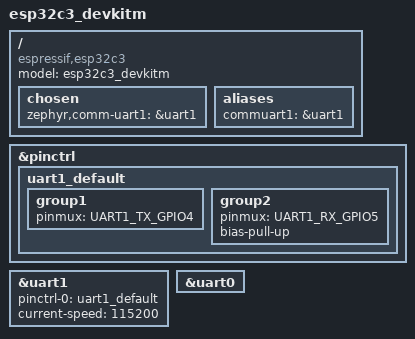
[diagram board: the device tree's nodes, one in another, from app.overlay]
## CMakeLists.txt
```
# SPDX-License-Identifier: Apache-2.0

cmake_minimum_required(VERSION 3.20.0)

find_package(Zephyr REQUIRED HINTS $ENV{ZEPHYR_BASE})
project(hello_world)

target_sources(app PRIVATE src/main.c)
target_include_directories(app PRIVATE 
    /home/user/csse4011/repo/oslib/scu_drivers/scu_sensors/
    /home/user/csse4011/repo/oslib/scu_drivers/scu_hci/
    /home/user/csse4011/repo/oslib/ahu_drivers/ahu_hci/)


target_sources(app PRIVATE
    src/main.c
    /home/user/csse4011/repo/oslib/scu_drivers/scu_sensors/scu_sensors.c
    /home/user/csse4011/repo/oslib/scu_drivers/scu_hci/scu_hci.c
    /home/user/csse4011/repo/oslib/ahu_drivers/ahu_hci/ahu_hci.c)
```

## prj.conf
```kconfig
CONFIG_GPIO=y
CONFIG_PRINTK=y
CONFIG_SERIAL=y
CONFIG_UART_INTERRUPT_DRIVEN=y
CONFIG_STDOUT_CONSOLE=y
CONFIG_I2C=y
CONFIG_SPI=y

#-----------------------------SHELL_CONF--------------------------------------
CONFIG_UART_LINE_CTRL=y
CONFIG_SHELL=y
CONFIG_SHELL_PROMPT_UART="CSSE4011:~$ "
CONFIG_SHELL_CMDS=y
CONFIG_SHELL_TAB=y
CONFIG_SHELL_TAB_AUTOCOMPLETION=y
CONFIG_SHELL_VT100_COLORS=y
#-----------------------------------------------------------------------------

#-----------------------------SHELL_LOGGING-----------------------------------
CONFIG_LOG=y
CONFIG_LOG_PRINTK=y
CONFIG_LOG_BACKEND_UART=y
#-----------------------------------------------------------------------------
```

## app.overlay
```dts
#include <espressif/esp32c3.dtsi>

/ {
    model = "esp32c3_devkitm";
    compatible = "espressif,esp32c3";
    chosen {
        zephyr,comm-uart1 = &uart1; // set UART1 for communication
    };

    aliases {
        commuart1 = &uart1; // create an alias for UART1
    };
};

&pinctrl {
    uart1_default: uart1_default {
        group1 {
            pinmux = < UART1_TX_GPIO4 >;
        };
        group2 {
            pinmux = < UART1_RX_GPIO5 >;
            bias-pull-up;
        };
    };
};

&uart1 {
    status = "okay";
    pinctrl-0 = < &uart1_default >;
    pinctrl-names = "default";
    current-speed = <115200>;
};

&uart0 {
    status = "okay";
};
```

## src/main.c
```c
/*
 * Copyright (c) 2022 Libre Solar Technologies GmbH
 *
 * SPDX-License-Identifier: Apache-2.0
 */

#include <zephyr/kernel.h>
#include <zephyr/device.h>
#include <zephyr/drivers/uart.h>
#include <stdio.h>
#include <string.h>

/* change this to any other UART peripheral if desired */
#define UART_DEVICE_NODE DT_ALIAS(commuart1)

#define MSG_SIZE 32

/* queue to store up to 10 messages (aligned to 4-byte boundary) */
K_MSGQ_DEFINE(uart_msgq, MSG_SIZE, 10, 4);

static const struct device *const uart_dev = DEVICE_DT_GET(UART_DEVICE_NODE);

/* receive buffer used in UART ISR callback */
static char rx_buf[MSG_SIZE];
static int rx_buf_pos;

/*
 * Read characters from UART until line end is detected. Afterwards push the
 * data to the message queue.
 */
void serial_cb(const struct device *dev, void *user_data)
{
	uint8_t c;

	if (!uart_irq_update(uart_dev)) {
		return;
	}

	if (!uart_irq_rx_ready(uart_dev)) {
		return;
	}

	/* read until FIFO empty */
	while (uart_fifo_read(uart_dev, &c, 1) == 1) {
		if ((c == '\n' || c == '\r') && rx_buf_pos > 0) {
			/* terminate string */
			rx_buf[rx_buf_pos] = '\0';

			/* if queue is full, message is silently dropped */
			k_msgq_put(&uart_msgq, &rx_buf, K_NO_WAIT);

			/* reset the buffer (it was copied to the msgq) */
			rx_buf_pos = 0;
		} else if (rx_buf_pos < (sizeof(rx_buf) - 1)) {
			rx_buf[rx_buf_pos++] = c;
		}
		/* else: characters beyond buffer size are dropped */
	}
}

/*
 * Print a null-terminated string character by character to the UART interface
 */
void print_uart(char *buf)
{
	int msg_len = strlen(buf);

	for (int i = 0; i < msg_len; i++) {
		uart_poll_out(uart_dev, buf[i]);
	}
}

/*
 * receives a null-terminated string character by character to the UART interface
 */
void recv_uart(char *buf)
{
	int msg_len = strlen(buf);

	for (int i = 0; i < msg_len; i++) {
		uart_poll_in(uart_dev, buf[i]);
	}
}

/* main function*/
void main(void)
{
	char tx_buf[MSG_SIZE];

	if (!device_is_ready(uart_dev)) {
		printk("UART device not found!");
		return;
	}

	/* configure interrupt and callback to receive data */
	int ret = uart_irq_callback_user_data_set(uart_dev, serial_cb, NULL);

	if (ret < 0) {
		if (ret == -ENOTSUP) {
			printk("Interrupt-driven UART API support not enabled\n");
		} else if (ret == -ENOSYS) {
			printk("UART device does not support interrupt-driven API\n");
		} else {
			printk("Error setting UART callback: %d\n", ret);
		}
		return;
	}
	uart_irq_rx_enable(uart_dev);

	//print_uart("Hello! I'm your echo bot.\r\n");
	//print_uart("Tell me something and press enter:\r\n");

		/* indefinitely wait for input from the user */
		while (k_msgq_get(&uart_msgq, &tx_buf, K_FOREVER) == 0) {
			//print_uart("Echo: ");
			//print_uart(tx_buf);
			tx_buf[0] = 'c';
			print_uart(tx_buf);
			printk("received: %c\n", rx_buf[0]);

			//print_uart("\r\n");
		}
 
}
```
